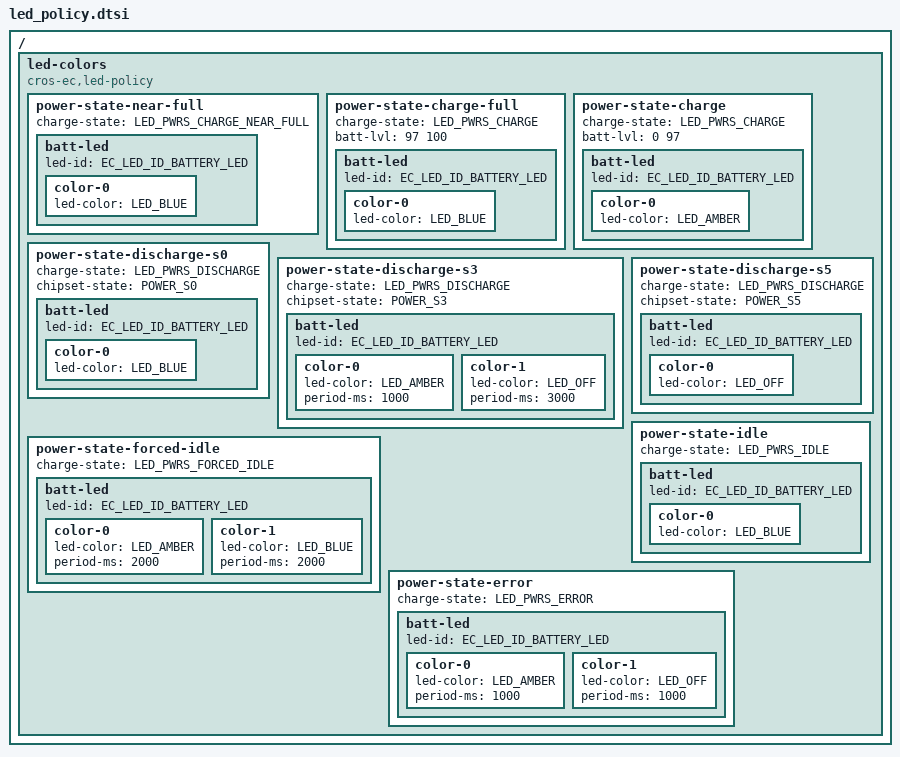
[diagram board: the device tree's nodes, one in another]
#include <dt-bindings/battery.h>

/ {
	led-colors {
		compatible = "cros-ec,led-policy";

		power-state-near-full {
			charge-state = "LED_PWRS_CHARGE_NEAR_FULL";

			/* Turn on Blue LED */
			batt-led {
				led-id = "EC_LED_ID_BATTERY_LED";
				color-0 {
					led-color = "LED_BLUE";
				};
			};
		};

		power-state-charge-full {
			charge-state = "LED_PWRS_CHARGE";
			/* Battery percent range 97..100 */
			batt-lvl = <97 100>;

			/* Turn on Blue LED */
			batt-led {
				led-id = "EC_LED_ID_BATTERY_LED";
				color-0 {
					led-color = "LED_BLUE";
				};
			};
		};

		power-state-charge {
			charge-state = "LED_PWRS_CHARGE";
			/* Battery percent range 0..97 */
			batt-lvl = <0 97>;

			/* Turn on Amber LED */
			batt-led {
				led-id = "EC_LED_ID_BATTERY_LED";
				color-0 {
					led-color = "LED_AMBER";
				};
			};
		};

		power-state-discharge-s0 {
			charge-state = "LED_PWRS_DISCHARGE";
			chipset-state = "POWER_S0";

			/* Turn on Blue LED */
			batt-led {
				led-id = "EC_LED_ID_BATTERY_LED";
				color-0 {
					led-color = "LED_BLUE";
				};
			};
		};

		power-state-discharge-s3 {
			charge-state = "LED_PWRS_DISCHARGE";
			chipset-state = "POWER_S3";

			/* One sec Amber, three secs Off */
			batt-led {
				led-id = "EC_LED_ID_BATTERY_LED";
				color-0 {
					led-color = "LED_AMBER";
					period-ms = <1000>;
				};
				color-1 {
					led-color = "LED_OFF";
					period-ms = <3000>;
				};
			};
		};

		power-state-discharge-s5 {
			charge-state = "LED_PWRS_DISCHARGE";
			chipset-state = "POWER_S5";

			/* Turn off */
			batt-led {
				led-id = "EC_LED_ID_BATTERY_LED";
				color-0 {
					led-color = "LED_OFF";
				};
			};
		};

		power-state-forced-idle {
			charge-state = "LED_PWRS_FORCED_IDLE";

			/* 2 secs Amber, 2 secs Blue */
			batt-led {
				led-id = "EC_LED_ID_BATTERY_LED";
				color-0 {
					led-color = "LED_AMBER";
					period-ms = <2000>;
				};
				color-1 {
					led-color = "LED_BLUE";
					period-ms = <2000>;
				};
			};
		};

		power-state-idle {
			charge-state = "LED_PWRS_IDLE";

			/* Turn on Blue LED */
			batt-led {
				led-id = "EC_LED_ID_BATTERY_LED";
				color-0 {
					led-color = "LED_BLUE";
				};
			};
		};

		power-state-error {
			charge-state = "LED_PWRS_ERROR";

			/* One sec Amber, one sec Off */
			batt-led {
				led-id = "EC_LED_ID_BATTERY_LED";
				color-0 {
					led-color = "LED_AMBER";
					period-ms = <1000>;
				};
				color-1 {
					led-color = "LED_OFF";
					period-ms = <1000>;
				};
			};
		};

	};
};
